# earlgrey register map
File version: 0.1
Address unit: 32 bits
Registers are 32-bit, read-write, no defined reset value unless marked. A register's access mark holds for its fields unless they carry their own. Offsets are from the block's base; [hi:lo] are bit positions.

## uart0 — Full duplex serial communication interface, supports bit rates of up to 1 Mbit/s
Base 0x40000000
Same registers: uart1 0x40010000, uart2 0x40020000, uart3 0x40030000
0x00 CTRL — UART control register
  [31:16] NCO — BAUD clock rate control.
  [9:8] RXBLVL — Trigger level for RX break detection. Sets the number of charactertimes the line must be low to detect a break.
    0=break2 (2 characters); 1=break4 (4 characters); 2=break8 (8 characters); 3=break16 (16 characters)
  [?] TX — TX enable
  [?] RX — RX enable
  [?] NF — RX noise filter enable.If the noise filter is enabled, RX line goes through the 3-taprepetition code. It ignores single IP clock period noise.
  [?] SLPBK — System loopback enable.If this bit is turned on, any outgoing bits to TX are received through RX.See Block Diagram. Note that the TX line goes 1 if System loopback is enabled.
  [?] LLPBK — Line loopback enable.If this bit is turned on, incoming bits are forwarded to TX for testing purpose.See Block Diagram. Note that the internal design sees RX value as 1 always if lineloopback is enabled.
  [?] PARITY_EN — If true, parity is enabled in both RX and TX directions.
  [?] PARITY_ODD — If PARITY_EN is true, this determines the type, 1 for odd parity, 0 for even.
0x20 STATUS ro — UART live status register
  [?] TXFULL — TX buffer is full
  [?] RXFULL — RX buffer is full
  [?] TXEMPTY — TX FIFO is empty
  [?] TXIDLE — TX FIFO is empty and all bits have been transmitted
  [?] RXIDLE — RX is idle
  [?] RXEMPTY — RX FIFO is empty
0x40 RDATA ro — UART read data
  [7:0] ?
0x60 WDATA wo — UART write data
  [7:0] ?
0x80 FIFO_CTRL — UART FIFO control register
  [6:5] TXILVL — Trigger level for TX interrupts. If the FIFO depth is less than the setting, itraises tx_watermark interrupt.
    0=txlvl1 (2 characters); 1=txlvl4 (4 characters); 2=txlvl8 (8 characters); 3=txlvl16 (16 characters)
  [4:2] RXILVL — Trigger level for RX interrupts. If the FIFO depth is greater than or equal tothe setting, it raises rx_watermark interrupt.
    0=rxlvl1 (1 character); 1=rxlvl4 (4 characters); 2=rxlvl8 (8 characters); 3=rxlvl16 (16 characters); 4=rxlvl30 (30 characters)
  [?] RXRST — RX fifo reset. Write 1 to the register resets RX_FIFO. Read returns 0
  [?] TXRST — TX fifo reset. Write 1 to the register resets TX_FIFO. Read returns 0
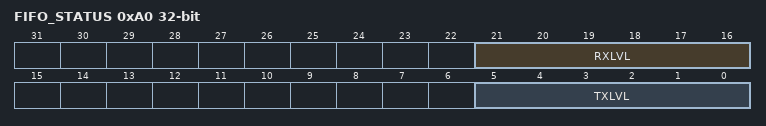
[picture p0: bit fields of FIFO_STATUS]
0xA0 FIFO_STATUS ro — UART FIFO status register
  [21:16] RXLVL — Current fill level of RX fifo
  [5:0] TXLVL — Current fill level of TX fifo
0xC0 OVRD — TX pin override control. Gives direct SW control over TX pin state
  [?] TXEN — Enable TX pin override control
  [?] TXVAL — Write to set the value of the TX pin
0xE0 VAL ro — UART oversampled values
  [15:0] RX — Last 16 oversampled values of RX. Most recent bit is bit 0, oldest 15.
0x100 TIMEOUT_CTRL — UART RX timeout control
  [23:0] VAL — RX timeout value in UART bit times
  [?] EN — Enable RX timeout feature

## gpio — General-purpose I/O pin control interface for software
Base 0x40040000
0x00 DATA_IN ro — GPIO Input data read value
  [31:0] ?
0x20 DIRECT_OUT — GPIO direct output data write value
  [31:0] ?
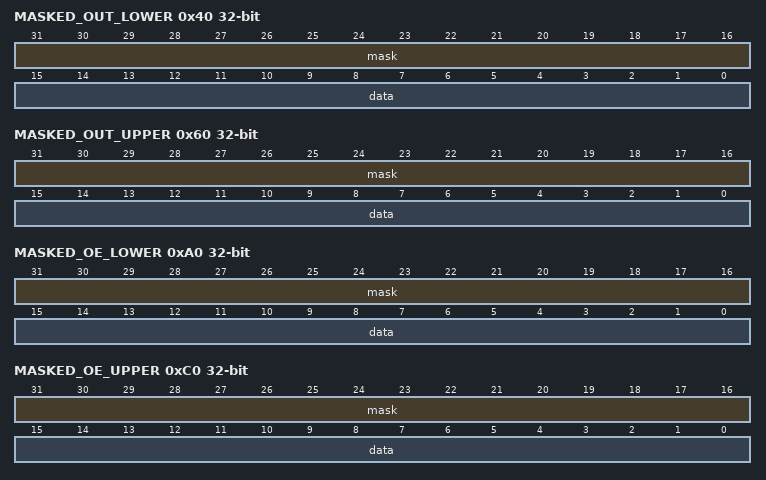
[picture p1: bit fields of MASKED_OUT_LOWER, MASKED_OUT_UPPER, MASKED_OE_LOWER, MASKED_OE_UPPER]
0x40 MASKED_OUT_LOWER — GPIO write data lower with mask.Masked write for DATA_OUT[15:0].Upper 16 bits of this register are used as mask. Writinglower 16 bits of the register changes DATA_OUT[15:0] valueif mask bits are set.Read-back of this register returns upper 16 bits as zeroand lower 16 bits as DATA_OUT[15:0].
  [31:16] mask — Write data mask[15:0].A value of 1 in mask[i] allows the updating of DATA_OUT[i], 0 = i = 15
  [15:0] data — Write data value[15:0].Value to write into DATA_OUT[i], valid in the presence of mask[i]==1
0x60 MASKED_OUT_UPPER — GPIO write data upper with mask.Masked write for DATA_OUT[31:16].Upper 16 bits of this register are used as mask. Writinglower 16 bits of the register changes DATA_OUT[31:16] valueif mask bits are set.Read-back of this register returns upper 16 bits as zeroand lower 16 bits as DATA_OUT[31:16].
  [31:16] mask — Write data mask[31:16].A value of 1 in mask[i] allows the updating of DATA_OUT[i], 16 = i = 31
  [15:0] data — Write data value[31:16]. Value to write into DATA_OUT[i], valid in the presence of mask[i]==1
0x80 DIRECT_OE — GPIO Output Enable.Setting direct_oe[i] to 1 enables output mode for GPIO[i]
  [31:0] ?
0xA0 MASKED_OE_LOWER — GPIO write Output Enable lower with mask.Masked write for DATA_OE[15:0], the register that controlsoutput mode for GPIO pins [15:0].Upper 16 bits of this register are used as mask. Writinglower 16 bits of the register changes DATA_OE[15:0] valueif mask bits are set.Read-back of this register returns upper 16 bits as zeroand lower 16 bits as DATA_OE[15:0].
  [31:16] mask — Write OE mask[15:0].A value of 1 in mask[i] allows the updating of DATA_OE[i], 0 = i = 15
  [15:0] data — Write OE value[15:0].Value to write into DATA_OE[i], valid in the presence of mask[i]==1
0xC0 MASKED_OE_UPPER — GPIO write Output Enable upper with mask.Masked write for DATA_OE[31:16], the register that controlsoutput mode for GPIO pins [31:16].Upper 16 bits of this register are used as mask. Writinglower 16 bits of the register changes DATA_OE[31:16] valueif mask bits are set.Read-back of this register returns upper 16 bits as zeroand lower 16 bits as DATA_OE[31:16].
  [31:16] mask — Write OE mask[31:16].A value of 1 in mask[i] allows the updating of DATA_OE[i], 16 = i = 31
  [15:0] data — Write OE value[31:16].Value to write into DATA_OE[i], valid in the presence of mask[i]==1
0xE0 INTR_CTRL_EN_RISING — GPIO interrupt enable for GPIO, rising edge.If !!INTR_ENABLE[i] is true, a value of 1 on !!INTR_CTRL_EN_RISING[i]enables rising-edge interrupt detection on GPIO[i].
  [31:0] ?
0x100 INTR_CTRL_EN_FALLING — GPIO interrupt enable for GPIO, falling edge.If !!INTR_ENABLE[i] is true, a value of 1 on !!INTR_CTRL_EN_FALLING[i]enables falling-edge interrupt detection on GPIO[i].
  [31:0] ?
0x120 INTR_CTRL_EN_LVLHIGH — GPIO interrupt enable for GPIO, level high.If !!INTR_ENABLE[i] is true, a value of 1 on !!INTR_CTRL_EN_LVLHIGH[i]enables level high interrupt detection on GPIO[i].
  [31:0] ?
0x140 INTR_CTRL_EN_LVLLOW — GPIO interrupt enable for GPIO, level low.If !!INTR_ENABLE[i] is true, a value of 1 on !!INTR_CTRL_EN_LVLLOW[i]enables level low interrupt detection on GPIO[i].
  [31:0] ?
0x160 CTRL_EN_INPUT_FILTER — filter enable for GPIO input bits.If !!CTRL_EN_INPUT_FILTER[i] is true, a value of input bit [i]must be stable for 16 cycles before transitioning.
  [31:0] ?

## clkmgr_aon — Derives and monitors on-chip clock signals, handles clock gating requests from power manager and software
Base 0x40420000
0x00 CLK_ENABLES — Clock enable for software gateable clocks.These clocks are direclty controlled by software.
  [?] CLK_FIXED_PERI_EN — 0 CLK_FIXED_PERI is disabled.1 CLK_FIXED_PERI is enabled.
  [?] CLK_USB_48MHZ_PERI_EN — 0 CLK_USB_48MHZ_PERI is disabled.1 CLK_USB_48MHZ_PERI is enabled.
0x20 CLK_HINTS — Clock hint for software gateable clocks.These clocks are not fully controlled by software.For disable, software only provides a hint, and hardware determines the final clock state based on thehint and whether the block in question is idle.
  [?] CLK_MAIN_AES_HINT — 0 CLK_MAIN_AES can be disabled.1 CLK_MAIN_AES is enabled.
  [?] CLK_MAIN_HMAC_HINT — 0 CLK_MAIN_HMAC can be disabled.1 CLK_MAIN_HMAC is enabled.
0x40 CLK_HINTS_STATUS ro — Since the final state of !!CLK_HINTS is not always determined by software,this register provides read feedback for the current clock state.
  [?] CLK_MAIN_AES_VAL — 0 CLK_MAIN_AES is disabled.1 CLK_MAIN_AES is enabled.
  [?] CLK_MAIN_HMAC_VAL — 0 CLK_MAIN_HMAC is disabled.1 CLK_MAIN_HMAC is enabled.

## aon_timer_aon — Wakeup and watchdog timers running on a low-power, always-on clock
Base 0x40470000
0x00 WKUP_CTRL — Wakeup Timer Control register
  [12:1] prescaler — Pre-scaler value for wakeup timer count
  [?] enable — When set to 1, the wakeup timer will count
0x20 WKUP_THOLD — Wakeup Timer Threshold Register
  [31:0] threshold — The count at which a wakeup interrupt should be generated
0x40 WKUP_COUNT — Wakeup Timer Count Register
  [31:0] count — The current wakeup counter value
0x60 WDOG_REGWEN rw0c — Watchdog Timer Write Enable Register
  [?] regwen — Once cleared, the watchdog configuration will be locked until the next reset
0x80 WDOG_CTRL — Watchdog Timer Control register
  [?] enable — When set to 1, the watchdog timer will count
  [?] pause_in_sleep — When set to 1, the watchdog timer will not count during sleep
0xA0 WDOG_BARK_THOLD — Watchdog Timer Bark Threshold Register
  [31:0] threshold — The count at which a watchdog bark interrupt should be generated
0xC0 WDOG_BITE_THOLD — Watchdog Timer Bite Threshold Register
  [31:0] threshold — The count at which a watchdog bite reset should be generated
0xE0 WDOG_COUNT — Watchdog Timer Count Register
  [31:0] count — The current watchdog counter value
0x100 INTR_STATE rw1c — Interrupt State Register
  [?] wkup_timer_expired — Raised if the wakeup timer has hit the specified threshold
  [?] wdog_timer_bark — Raised if the watchdog timer has hit the bark threshold
0x120 INTR_TEST wo — Interrupt Test Register
  [?] wkup_timer_expired — Write 1 to force wkup_timer_expired interrupt
  [?] wdog_timer_bark — Write 1 to force wdog_timer_bark interrupt
0x140 WKUP_CAUSE rw0c — Wakeup request status
  [?] cause — AON timer requested wakeup, write 0 to clear
